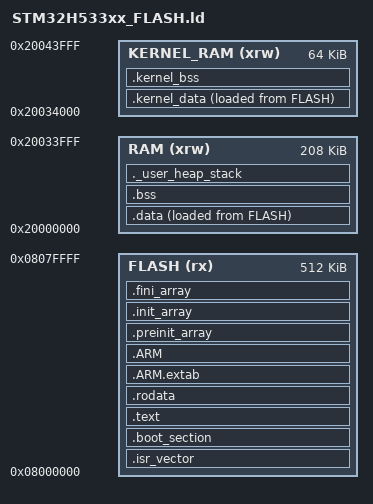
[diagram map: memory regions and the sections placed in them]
/*
 ******************************************************************************
 **
 ** @file        : STM32H533xx_FLASH.ld
 **
 ** @author      : Auto-generated by STM32CubeIDE
 **
 ** @brief       : Linker script for STM32H533xx Device from STM32H5 series
 **                      512Kbytes FLASH
 **                      272Kbytes RAM
 **
 **                Set heap size, stack size and stack location according
 **                to application requirements.
 **
 **                Set memory bank area and size if external memory is used
 **
 **  Target      : STMicroelectronics STM32
 **
 **  Distribution: The file is distributed as is, without any warranty
 **                of any kind.
 **
 ******************************************************************************
 ** @attention
 **
 ** Copyright (c) 2023 STMicroelectronics.
 ** All rights reserved.
 **
 ** This software is licensed under terms that can be found in the LICENSE file
 ** in the root directory of this software component.
 ** If no LICENSE file comes with this software, it is provided AS-IS.
 **
 ******************************************************************************
 */

/* Reset handler provided by the startup assembly. */
ENTRY(Reset_Handler)

/* The kernel stack starts at the top of the dedicated kernel RAM region. */
_estack = ORIGIN(KERNEL_RAM) + LENGTH(KERNEL_RAM);

/* Minimum space reserved for the application heap and stacks. */
_Min_Heap_Size         = 0x200;
_Min_Stack_Size        = 0x8000;
_Min_kernel_Stack_Size = 0x400;
/*
 * Memory map:
 *   - RAM holds application data, BSS, heap, and user stack reservations.
 *   - KERNEL_RAM isolates kernel data, BSS, and the kernel stack.
 *   - FLASH holds executable code, constants, and data load images.
 */
MEMORY
{
  RAM        (xrw) : ORIGIN = 0x20000000, LENGTH = 208K
  KERNEL_RAM (xrw) : ORIGIN = 0x20034000, LENGTH = 64K
  FLASH      (rx)  : ORIGIN = 0x08000000, LENGTH = 512K
}

_sFlash = ORIGIN(FLASH);
_eFlash =ORIGIN(FLASH) + LENGTH(FLASH);
/* Full kernel SRAM bounds used by the MPU configuration. */
_skernel_ram = ORIGIN(KERNEL_RAM);
_ekernel_ram = ORIGIN(KERNEL_RAM) + LENGTH(KERNEL_RAM);

/* Sections */
SECTIONS
{
  /* Interrupt vector table; KEEP prevents garbage collection. */
  .isr_vector :
  {
    . = ALIGN(4);
    KEEP(*(.isr_vector)) /* Startup code */
    . = ALIGN(4);
  } >FLASH

  /* Early startup routines required before RAM is initialized. */
  .boot_section :
  {
    KEEP(*(.boot_section))
  } >FLASH

  /* The program code and other data into "FLASH" Rom type memory */
  .text :
  {
    . = ALIGN(4);
    *(.text)           /* .text sections (code) */
    *(.text*)          /* .text* sections (code) */
    *(.glue_7)         /* glue arm to thumb code */
    *(.glue_7t)        /* glue thumb to arm code */
    *(.eh_frame)

    KEEP (*(.init))
    KEEP (*(.fini))

    . = ALIGN(4);
    _etext = .;        /* define a global symbols at end of code */
  } >FLASH

  /* Constant data into "FLASH" Rom type memory */
  .rodata :
  {
    . = ALIGN(4);
    *(.rodata)         /* .rodata sections (constants, strings, etc.) */
    *(.rodata*)        /* .rodata* sections (constants, strings, etc.) */
    . = ALIGN(4);
  } >FLASH

  .ARM.extab (READONLY) : /* The READONLY keyword is only supported in GCC11 and later, remove it if using GCC10 or earlier. */
  {
    . = ALIGN(4);
    *(.ARM.extab* .gnu.linkonce.armextab.*)
    . = ALIGN(4);
  } >FLASH

  .ARM (READONLY) : /* The READONLY keyword is only supported in GCC11 and later, remove it if using GCC10 or earlier. */
  {
    . = ALIGN(4);
    __exidx_start = .;
    *(.ARM.exidx*)
    __exidx_end = .;
    . = ALIGN(4);
  } >FLASH

  .preinit_array (READONLY) : /* The READONLY keyword is only supported in GCC11 and later, remove it if using GCC10 or earlier. */
  {
    . = ALIGN(4);
    PROVIDE_HIDDEN (__preinit_array_start = .);
    KEEP (*(.preinit_array*))
    PROVIDE_HIDDEN (__preinit_array_end = .);
    . = ALIGN(4);
  } >FLASH

  .init_array (READONLY) : /* The READONLY keyword is only supported in GCC11 and later, remove it if using GCC10 or earlier. */
  {
    . = ALIGN(4);
    PROVIDE_HIDDEN (__init_array_start = .);
    KEEP (*(SORT(.init_array.*)))
    KEEP (*(.init_array*))
    PROVIDE_HIDDEN (__init_array_end = .);
    . = ALIGN(4);
  } >FLASH

  .fini_array (READONLY) : /* The READONLY keyword is only supported in GCC11 and later, remove it if using GCC10 or earlier. */
  {
    . = ALIGN(4);
    PROVIDE_HIDDEN (__fini_array_start = .);
    KEEP (*(SORT(.fini_array.*)))
    KEEP (*(.fini_array*))
    PROVIDE_HIDDEN (__fini_array_end = .);
    . = ALIGN(4);
  } >FLASH

  /* Flash load address used by startup code to initialize application data. */
  _sidata = LOADADDR(.data);

  /* Initialized application data: executes in RAM, loaded from FLASH. */
  .data :
  {
      . = ALIGN(32);
    _sdata = .;        /* create a global symbol at data start */
    *(.data)           /* .data sections */
    *(.data*)          /* .data* sections */
    *(.RamFunc)        /* .RamFunc sections */
    *(.RamFunc*)       /* .RamFunc* sections */

    . = ALIGN(4);
    _edata = .;        /* define a global symbol at data end */

  } >RAM AT> FLASH

  /* Zero-initialized application data. */
  . = ALIGN(4);
  .bss :
  {
    /* This is used by the startup in order to initialize the .bss section */
    _sbss = .;         /* define a global symbol at bss start */
    __bss_start__ = _sbss;
    *(.bss)
    *(.bss*)
    *(COMMON)

     . = ALIGN(32);
    _ebss = .;         /* define a global symbol at bss end */
    __bss_end__ = _ebss;
  } >RAM

  /* Reserve application heap and stack space and detect RAM overflow at link time. */
._user_heap_stack  :
{
    . = ALIGN(32);
    PROVIDE(end = .);
    PROVIDE(_end = .);

    PROVIDE(_suser_heap = .);
    . = . + _Min_Heap_Size;
    . = ALIGN(32);
    PROVIDE(_euser_heap = .);

    /* Lowest accessible address of the stack. */
    . = ALIGN(32);
    PROVIDE(_suser_stack = .);
    . = . + _Min_Stack_Size;
    . = ALIGN(32);

    /* Initial stack pointer; end-exclusive stack address. */
    PROVIDE(_euser_stack = .);
} > RAM

  /* Initialized kernel data: executes in KERNEL_RAM, loaded from FLASH. */
  .kernel_data :
  {
    . = ALIGN(32);
    PROVIDE(_skernel_data = .);
    PROVIDE(_skernel_ram = .);
    *(.kernel_data)
    *(.kernel_data*)
     . = ALIGN(4);
    _ekernel_data = .;
   

  } >KERNEL_RAM AT>FLASH

  /* Zero-initialized kernel data. */
  .kernel_bss :
  {
    . = ALIGN(4);
    _skernel_bss = .;
    *(.kernel_bss)
    *(.kernel_bss*)
    . = ALIGN(4);
    _ekernel_bss = .;
  } >KERNEL_RAM

  /* Reserve the kernel stack at the end of the kernel bss region. */
  _kernel_stack_bottom = ORIGIN(KERNEL_RAM) + LENGTH(KERNEL_RAM) - _Min_kernel_Stack_Size;

  PROVIDE(_skernel_stack = _kernel_stack_bottom);
  PROVIDE(_ekernel_stack = _estack);

  ASSERT(
      _ekernel_bss <= _kernel_stack_bottom,
      "Kernel RAM overflow: kernel data overlaps MSP stack")

  /* Kernel data load address and byte count consumed by startup code. */
  _sikernel_data = LOADADDR(.kernel_data);
  _sizekernel_data = SIZEOF(.kernel_data);
  _sizedata = SIZEOF(.data);
  /* Remove information from the compiler libraries */
  /DISCARD/ :
  {
    libc.a ( * )
    libm.a ( * )
    libgcc.a ( * )
  }

  .ARM.attributes 0 : { *(.ARM.attributes) }
}
